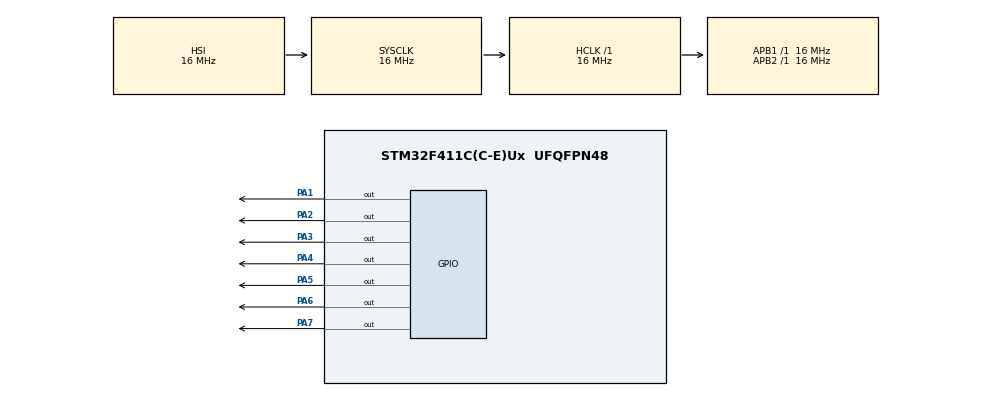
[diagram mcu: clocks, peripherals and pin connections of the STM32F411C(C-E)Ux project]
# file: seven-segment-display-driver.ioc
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Mcu.Family=STM32F4
Mcu.Name=STM32F411C(C-E)Ux
Mcu.Package=UFQFPN48
NVIC.PriorityGroup=NVIC_PRIORITYGROUP_4
PA1.Signal=GPIO_Output
PA2.Signal=GPIO_Output
PA3.Signal=GPIO_Output
PA4.Signal=GPIO_Output
PA5.Signal=GPIO_Output
PA6.Signal=GPIO_Output
PA7.Signal=GPIO_Output
ProjectManager.HeapSize=0x200
ProjectManager.StackSize=0x400
ProjectManager.TargetToolchain=STM32CubeIDE
RCC.AHBFreq_Value=16000000
RCC.APB1Freq_Value=16000000
RCC.APB2Freq_Value=16000000
RCC.CortexFreq_Value=16000000
RCC.HSE_VALUE=25000000
RCC.HSI_VALUE=16000000
RCC.LSE_VALUE=32768
RCC.SYSCLKFreq_VALUE=16000000
RCC.VCOOutputFreq_Value=192000000
board=custom

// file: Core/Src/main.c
/* USER CODE BEGIN Header */
/**
  ******************************************************************************
  * @file           : main.c
  * @brief          : Main program body
  ******************************************************************************
  * @attention
  *
  * Copyright (c) 2026 STMicroelectronics.
  * All rights reserved.
  *
  * This software is licensed under terms that can be found in the LICENSE file
  * in the root directory of this software component.
  * If no LICENSE file comes with this software, it is provided AS-IS.
  *
  ******************************************************************************
  */
/* USER CODE END Header */
#include "main.h"

/* USER CODE BEGIN Includes */
#include "seven_segment.h"
/* USER CODE END Includes */

/* USER CODE BEGIN PV */
//int mainCnt = 0;

/* USER CODE END PV */

void SystemClock_Config(void);
static void MX_GPIO_Init(void);

int main(void)
{

  /* USER CODE BEGIN 1 */
	seven_seg_pin pins[7] =
	{
	    {GPIOA, GPIO_PIN_1},
	    {GPIOA, GPIO_PIN_2},
	    {GPIOA, GPIO_PIN_3},
	    {GPIOA, GPIO_PIN_4},
	    {GPIOA, GPIO_PIN_5},
	    {GPIOA, GPIO_PIN_6},
	    {GPIOA, GPIO_PIN_7}
	};

  /* USER CODE END 1 */

  /* MCU Configuration--------------------------------------------------------*/

  /* Reset of all peripherals, Initializes the Flash interface and the Systick. */
  HAL_Init();

  /* Configure the system clock */
  SystemClock_Config();

  /* Initialize all configured peripherals */
  MX_GPIO_Init();

  /* Infinite loop */
  while (1)
  {

    /* USER CODE BEGIN 3 */
//	  HAL_GPIO_TogglePin(GPIOC, GPIO_PIN_13);
//	  HAL_GPIO_WritePin(GPIOA, GPIO_PIN_1, 1);
//	  HAL_Delay(500);
//	  mainCnt++;
//	  HAL_GPIO_WritePin(GPIOA, GPIO_PIN_1, 0);
//	  HAL_GPIO_WritePin(GPIOA, GPIO_PIN_2, 0);
//	  HAL_GPIO_WritePin(GPIOA, GPIO_PIN_3, 0);
//	  HAL_GPIO_WritePin(GPIOA, GPIO_PIN_4, 0);
//	  HAL_GPIO_WritePin(GPIOA, GPIO_PIN_5, 0);
//	  HAL_GPIO_WritePin(GPIOA, GPIO_PIN_6, 0);
//	  HAL_GPIO_WritePin(GPIOA, GPIO_PIN_7, 0);

	  seven_segment_set_digit(pins, 0,COMMON_ANNODE);
//	  HAL_Delay(500);
  }
  /* USER CODE END 3 */
}

void SystemClock_Config(void)
{
  RCC_OscInitTypeDef RCC_OscInitStruct = {0};
  RCC_ClkInitTypeDef RCC_ClkInitStruct = {0};

  /** Configure the main internal regulator output voltage
  */
  __HAL_RCC_PWR_CLK_ENABLE();
  __HAL_PWR_VOLTAGESCALING_CONFIG(PWR_REGULATOR_VOLTAGE_SCALE1);

  /** Initializes the RCC Oscillators according to the specified parameters
  * in the RCC_OscInitTypeDef structure.
  */
  RCC_OscInitStruct.OscillatorType = RCC_OSCILLATORTYPE_HSI;
  RCC_OscInitStruct.HSIState = RCC_HSI_ON;
  RCC_OscInitStruct.HSICalibrationValue = RCC_HSICALIBRATION_DEFAULT;
  RCC_OscInitStruct.PLL.PLLState = RCC_PLL_NONE;
  if (HAL_RCC_OscConfig(&RCC_OscInitStruct) != HAL_OK)
  {
    Error_Handler();
  }

  /** Initializes the CPU, AHB and APB buses clocks
  */
  RCC_ClkInitStruct.ClockType = RCC_CLOCKTYPE_HCLK|RCC_CLOCKTYPE_SYSCLK
                              |RCC_CLOCKTYPE_PCLK1|RCC_CLOCKTYPE_PCLK2;
  RCC_ClkInitStruct.SYSCLKSource = RCC_SYSCLKSOURCE_HSI;
  RCC_ClkInitStruct.AHBCLKDivider = RCC_SYSCLK_DIV1;
  RCC_ClkInitStruct.APB1CLKDivider = RCC_HCLK_DIV1;
  RCC_ClkInitStruct.APB2CLKDivider = RCC_HCLK_DIV1;

  if (HAL_RCC_ClockConfig(&RCC_ClkInitStruct, FLASH_LATENCY_0) != HAL_OK)
  {
    Error_Handler();
  }
}

static void MX_GPIO_Init(void)
{
  GPIO_InitTypeDef GPIO_InitStruct = {0};

  /* GPIO Ports Clock Enable */
  __HAL_RCC_GPIOC_CLK_ENABLE();
  __HAL_RCC_GPIOA_CLK_ENABLE();

  /*Configure GPIO pin Output Level */
  HAL_GPIO_WritePin(GPIOC, GPIO_PIN_13, GPIO_PIN_RESET);

  /*Configure GPIO pin Output Level */
  HAL_GPIO_WritePin(GPIOA, GPIO_PIN_1|GPIO_PIN_2|GPIO_PIN_3|GPIO_PIN_4
                          |GPIO_PIN_5|GPIO_PIN_6|GPIO_PIN_7, GPIO_PIN_RESET);

  /*Configure GPIO pin : PC13 */
  GPIO_InitStruct.Pin = GPIO_PIN_13;
  GPIO_InitStruct.Mode = GPIO_MODE_OUTPUT_PP;
  GPIO_InitStruct.Pull = GPIO_NOPULL;
  GPIO_InitStruct.Speed = GPIO_SPEED_FREQ_LOW;
  HAL_GPIO_Init(GPIOC, &GPIO_InitStruct);

  /*Configure GPIO pins : PA1 PA2 PA3 PA4
                           PA5 PA6 PA7 */
  GPIO_InitStruct.Pin = GPIO_PIN_1|GPIO_PIN_2|GPIO_PIN_3|GPIO_PIN_4
                          |GPIO_PIN_5|GPIO_PIN_6|GPIO_PIN_7;
  GPIO_InitStruct.Mode = GPIO_MODE_OUTPUT_PP;
  GPIO_InitStruct.Pull = GPIO_NOPULL;
  GPIO_InitStruct.Speed = GPIO_SPEED_FREQ_LOW;
  HAL_GPIO_Init(GPIOA, &GPIO_InitStruct);

}

void Error_Handler(void)
{
  __disable_irq();
  while (1)
  {
  }
}
